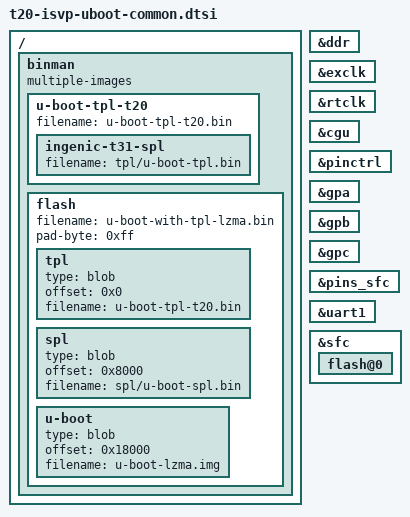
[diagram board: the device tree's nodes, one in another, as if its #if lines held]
// SPDX-License-Identifier: GPL-2.0+
/*
 * Shared U-Boot overlay for the Ingenic ISVP-T20 SFC-NOR leaf DTs.
 * Each per-SKU <leaf>-u-boot.dtsi is a one-line include of this file.
 *
 * Provides the binman image description for the SFC-NOR boot. The T20
 * mask ROM SFC-NOR boot path is the common XBurst1 one (the 2 KiB header
 * CRC7+length finalized by the ingenic-t31-spl binman etype - that header
 * format is family-generic, emitted by the shared start.S, not
 * T31-specific):
 *
 *   u-boot-spl-t20.bin       : SPL with the finalized boot header.
 *   u-boot-with-spl-lzma.bin : headered SPL at offset 0 and LZMA U-Boot
 *                              at the SPL-loader offset.
 *
 * Also tags the SPL-needed nodes bootph-all so they survive into the SPL
 * devicetree: the SPL probes the DDR node (UCLASS_RAM) and loads U-Boot
 * proper from NOR via the DM SFC driver. T20 has only PA..PC (no PD).
 */

/ {
	binman: binman {
		multiple-images;
	};
};

&binman {
#ifdef CONFIG_TPL
	/*
	 * TPL boot chain (all within the 320 KiB / 0x50000 bootloader budget
	 * before the environment): the mask ROM loads the headered TPL at
	 * offset 0; the TPL brings up DDR and reads the DRAM-resident SPL from
	 * 0x8000 (= T20_TPL_SPL_NOR_OFFS); the SPL reads U-Boot from 0x18000
	 * (= CONFIG_SYS_SPI_U_BOOT_OFFS). Env stays at 0x50000.
	 */
	u-boot-tpl-t20 {
		filename = "u-boot-tpl-t20.bin";

		ingenic-t31-spl {
			filename = "tpl/u-boot-tpl.bin";
		};
	};

	flash {
		filename = "u-boot-with-tpl-lzma.bin";
		pad-byte = <0xff>;

		tpl {
			type = "blob";
			offset = <0x0>;
			filename = "u-boot-tpl-t20.bin";
		};

		spl {
			type = "blob";
			offset = <0x8000>;
			filename = "spl/u-boot-spl.bin";
		};

		u-boot {
			type = "blob";
			offset = <0x18000>;
			filename = "u-boot-lzma.img";
		};
	};
#else
	u-boot-spl-t20 {
		filename = "u-boot-spl-t20.bin";

		ingenic-t31-spl {
			filename = "spl/u-boot-spl.bin";
		};
	};

	flash {
		filename = "u-boot-with-spl-lzma.bin";
		pad-byte = <0xff>;

		spl {
			type = "blob";
			offset = <0x0>;
			filename = "u-boot-spl-t20.bin";
		};

		u-boot {
			type = "blob";
			offset = <0x10000>;
			filename = "u-boot-lzma.img";
		};
	};
#endif
};

/*
 * Phase tags. The SPL/TPL devicetrees are fdtgrep-filtered out of the single
 * U-Boot dt.dtb by these bootph tags (TPL keeps bootph-all + bootph-pre-sram;
 * SPL keeps bootph-all + bootph-pre-ram) - they are NOT re-preprocessed per
 * phase, so the split must be expressed in the tags, not with #ifdef.
 *
 * The TPL is a cache-as-RAM DDR loader whose ONLY DM device is the DDR
 * controller: its probe brings up PLL + DDR, then it hand-loads the SPL with
 * bare-metal SFC/serial helpers (no DM SFC/pinctrl/gpio/uart). So &ddr is the
 * only node tagged for all phases; tagging the full NOR/console set for the
 * TPL would pull in uclasses the minimal TPL doesn't build and fail the
 * OF_PLATDATA scan with -EINVAL.
 *
 * Every other node is tagged bootph-pre-ram + bootph-some-ram (= bootph-all
 * minus the TPL/pre-sram phase): present in the SPL DM NOR boot and bound
 * pre-relocation in U-Boot proper exactly as before, absent from the TPL.
 */
&ddr { bootph-all; };		/* the TPL's only DM device */

&exclk { bootph-pre-ram; bootph-some-ram; };
&rtclk { bootph-pre-ram; bootph-some-ram; };
&cgu { bootph-pre-ram; bootph-some-ram; };
&pinctrl { bootph-pre-ram; bootph-some-ram; };
&gpa { bootph-pre-ram; bootph-some-ram; };
&gpb { bootph-pre-ram; bootph-some-ram; };
&gpc { bootph-pre-ram; bootph-some-ram; };
&pins_sfc { bootph-pre-ram; bootph-some-ram; };
&uart1 { bootph-pre-ram; bootph-some-ram; };
&sfc {
	bootph-pre-ram;
	bootph-some-ram;
	flash@0 {
		bootph-pre-ram;
		bootph-some-ram;
	};
};
